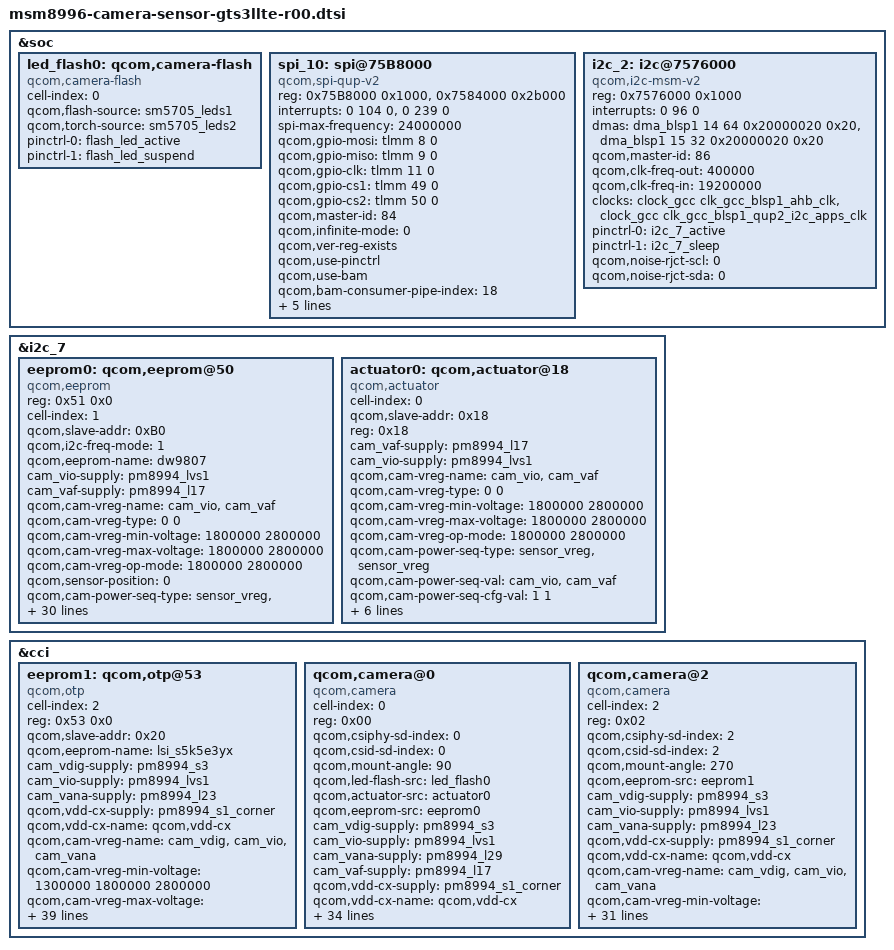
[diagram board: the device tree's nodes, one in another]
/*
 * Copyright (c) 2015 The Linux Foundation. All rights reserved.
 *
 * This program is free software; you can redistribute it and/or modify
 * it under the terms of the GNU General Public License version 2 and
 * only version 2 as published by the Free Software Foundation.
 *
 * This program is distributed in the hope that it will be useful,
 * but WITHOUT ANY WARRANTY; without even the implied warranty of
 * MERCHANTABILITY or FITNESS FOR A PARTICULAR PURPOSE.  See the
 * GNU General Public License for more details.
 */

&soc {
	led_flash0: qcom,camera-flash {
		cell-index = <0>;
		compatible = "qcom,camera-flash";
		qcom,flash-source = <&sm5705_leds1>;
		qcom,torch-source = <&sm5705_leds2>;
		pinctrl-names = "flash_default", "flash_suspend";
		pinctrl-0 = <&flash_led_active>;
		pinctrl-1 = <&flash_led_suspend>;
	};
};

&soc {
	spi_10: spi@75B8000 { /* BLSP2 QUP4 */
		compatible = "qcom,spi-qup-v2";

		reg-names = "spi_physical", "spi_bam_physical";
		reg = <0x75B8000 0x1000>, <0x7584000 0x2b000>;
		interrupt-names = "spi_irq", "spi_bam_irq";
		interrupts = <0 104 0>, <0 239 0>;

		spi-max-frequency = <24000000>;
		#address-cells = <1>;
		#size-cells = <0>;

		qcom,gpio-mosi = <&tlmm 8 0>;
		qcom,gpio-miso = <&tlmm 9 0>;
		qcom,gpio-clk  = <&tlmm 11 0>;
		qcom,gpio-cs1  = <&tlmm 49 0>;
		qcom,gpio-cs2  = <&tlmm 50 0>;

		qcom,master-id = <84>;
		qcom,infinite-mode = <0>;
		qcom,ver-reg-exists;
		qcom,use-pinctrl;
		qcom,use-bam;
		qcom,bam-consumer-pipe-index = <18>;
		qcom,bam-producer-pipe-index = <19>;
		pinctrl-names = "spi_default", "spi_sleep";
		pinctrl-0 = <&spi_10_active &spi_10_cs1_active>;
		pinctrl-1 = <&spi_10_sleep &spi_10_cs1_sleep>;

		clock-names = "iface_clk", "core_clk";

		clocks = <&clock_gcc clk_gcc_blsp2_ahb_clk>,
			 <&clock_gcc clk_gcc_blsp2_qup4_spi_apps_clk>;
	};

	i2c_2: i2c@7576000 { /* BLSP1 QUP2 */
		compatible = "qcom,i2c-msm-v2";
		#address-cells = <1>;
		#size-cells = <0>;
		reg-names = "qup_phys_addr";
		reg = <0x7576000 0x1000>;
		interrupt-names = "qup_irq";
		interrupts = <0 96 0>;
		dmas = <&dma_blsp1 14 64 0x20000020 0x20>,
			<&dma_blsp1 15 32 0x20000020 0x20>;
		dma-names = "tx", "rx";
		qcom,master-id = <86>;
		qcom,clk-freq-out = <400000>;
		qcom,clk-freq-in  = <19200000>;
		clock-names = "iface_clk", "core_clk";
		clocks = <&clock_gcc clk_gcc_blsp1_ahb_clk>,
			<&clock_gcc clk_gcc_blsp1_qup2_i2c_apps_clk>;
		pinctrl-names = "i2c_active", "i2c_sleep";
		pinctrl-0 = <&i2c_7_active>;
		pinctrl-1 = <&i2c_7_sleep>;
		qcom,noise-rjct-scl = <0>;
		qcom,noise-rjct-sda = <0>;
	};
};

&i2c_7 {
	eeprom0: qcom,eeprom@50 {
		compatible = "qcom,eeprom";
		reg = <0x51 0x0>;
		cell-index = <1>;
		qcom,slave-addr = <0xB0>;
		qcom,i2c-freq-mode = <1>;
		qcom,eeprom-name = "dw9807";
		cam_vio-supply = <&pm8994_lvs1>;
		cam_vaf-supply = <&pm8994_l17>;
		qcom,cam-vreg-name = "cam_vio", "cam_vaf";
		qcom,cam-vreg-type = <0 0>;
		qcom,cam-vreg-min-voltage = <1800000 2800000>;
		qcom,cam-vreg-max-voltage = <1800000 2800000>;
		qcom,cam-vreg-op-mode = <1800000 2800000>;

		qcom,sensor-position = <0>;
		qcom,cam-power-seq-type = "sensor_vreg", "sensor_vreg";
		qcom,cam-power-seq-val = "cam_vio", "cam_vaf";
		qcom,cam-power-seq-cfg-val = <1 1>;
		qcom,cam-power-seq-delay = <2 20>;

		qcom,num-blocks = <8>;
		qcom,page0 = <0 0x0 0 0x0 0 0>;
		qcom,poll0 = <0 0x0 0 0x0 0 0>;
		qcom,mem0 = <0xFC 0x0 2 0 1 0>;

		qcom,page1 = <0 0x0 0 0x0 0 0>;
		qcom,poll1 = <0 0x0 0 0x0 0 0>;
		qcom,mem1 = <0x4 0xFC 2 0 1 0>;

		qcom,page2 = <0 0x0 0 0x0 0 0>;
		qcom,poll2 = <0 0x0 0 0x0 0 0>;
		qcom,mem2 = <0x7B0 0x100 2 0 1 0>;

		qcom,page3 = <0 0x0 0 0x0 0 0>;
		qcom,poll3 = <0 0x0 0 0x0 0 0>;
		qcom,mem3 = <0x4 0x8FC 2 0 1 0>;

		qcom,page4 = <0 0x0 0 0x0 0 0>;
		qcom,poll4 = <0 0x0 0 0x0 0 0>;
		qcom,mem4 = <0x20 0x900 2 0 1 0>;

		qcom,page5 = <0 0x0 0 0x0 0 0>;
		qcom,poll5 = <0 0x0 0 0x0 0 0>;
		qcom,mem5 = <0x4 0x9FC 2 0 1 0>;

		qcom,page6 = <0 0x0 0 0x0 0 0>;
		qcom,poll6 = <0 0x0 0 0x0 0 0>;
		qcom,mem6 = <0x700 0xA00 2 0 1 0>;

		qcom,page7 = <0 0x0 0 0x0 0 0>;
		qcom,poll7 = <0 0x0 0 0x0 0 0>;
		qcom,mem7 = <0x4 0x11FC 2 0 1 0>;

		qcom,total-size = <0x1200>;
	};

	actuator0: qcom,actuator@18 {
		compatible = "qcom,actuator";
		cell-index = <0>;
		qcom,slave-addr = <0x18>;
		reg = <0x18>;
		cam_vaf-supply = <&pm8994_l17>;
		cam_vio-supply = <&pm8994_lvs1>;
		qcom,cam-vreg-name = "cam_vio", "cam_vaf";
		qcom,cam-vreg-type = <0 0>;
		qcom,cam-vreg-min-voltage = <1800000 2800000>;
		qcom,cam-vreg-max-voltage = <1800000 2800000>;
		qcom,cam-vreg-op-mode = <1800000 2800000>;

		qcom,cam-power-seq-type = "sensor_vreg", "sensor_vreg";
		qcom,cam-power-seq-val = "cam_vio", "cam_vaf";
		qcom,cam-power-seq-cfg-val = <1 1>;
		qcom,cam-power-seq-delay = <2 1>;

		gpios = <&tlmm 55 0>,
			<&tlmm 56 0>;
		qcom,gpio-req-tbl-num = <0 1>;
		qcom,gpio-req-tbl-flags = <1 1>;
		qcom,gpio-req-tbl-label = "I2C_DATA0",
					  "I2C_CLK0";
		qcom,cci-master = <0>;
	};

};

&spi_10 {

};

&cci {
	eeprom1: qcom,otp@53 {
		cell-index = <2>;
		compatible = "qcom,otp";
		reg = <0x53 0x0>;
		qcom,slave-addr = <0x20>;
		qcom,eeprom-name = "lsi_s5k5e3yx";
		cam_vdig-supply = <&pm8994_s3>;
		cam_vio-supply = <&pm8994_lvs1>;
		cam_vana-supply = <&pm8994_l23>;
		qcom,vdd-cx-supply = <&pm8994_s1_corner>;
		qcom,vdd-cx-name = "qcom,vdd-cx";
		qcom,cam-vreg-name = "cam_vdig", "cam_vio", "cam_vana";
		qcom,cam-vreg-min-voltage = <1300000 1800000 2800000>;
		qcom,cam-vreg-max-voltage = <1300000 1800000 2800000>;
		qcom,cam-vreg-op-mode = <1300000 1800000 2800000>;
		pinctrl-names = "cam_default", "cam_suspend";
		pinctrl-0 = <&cam_sensor_mclk2_active &cam_sensor_front_active>;
		pinctrl-1 = <&cam_sensor_mclk2_suspend &cam_sensor_front_suspend>;
		qcom,gpio-no-mux = <0>;
		gpios = <&tlmm 15 0>,
			<&tlmm 8 0>,
			<&tlmm 40 0>;
		qcom,gpio-vdig = <1>;
		qcom,gpio-reset = <2>;
		qcom,gpio-req-tbl-num = <0 1 2>;
		qcom,gpio-req-tbl-flags = <1 0 0 >;
		qcom,gpio-req-tbl-label = "CAMIF_MCLK",
			"CAM_VDIG",
			"CAM_RESET";
		qcom,sensor-position = <1>;
		qcom,sensor-mode = <0>;
		qcom,cci-master = <1>;
		status = "ok";

		qcom,cam-power-seq-type = "sensor_vreg", "sensor_gpio", "sensor_vreg", "sensor_vreg", "sensor_gpio", "sensor_clk";
		qcom,cam-power-seq-val = "cam_vana", "sensor_gpio_vdig", "cam_vdig", "cam_vio", "sensor_gpio_reset", "sensor_cam_mclk";
		qcom,cam-power-seq-cfg-val = <1 1 1 1 1 24000000>;
		qcom,cam-power-seq-delay = <1 1 1 1 2 5>;

		clocks = <&clock_mmss clk_mclk2_clk_src>,
			<&clock_mmss clk_camss_mclk2_clk>;
		clock-names = "cam_src_clk", "cam_clk";
		qcom,clock-rates = <24000000 0>;

		qcom,num-blocks = <3>;
		qcom,page0 = <0 0 0 0 0 0>;
		qcom,poll0 = <0 0 0 0 0 0>;
		qcom,mem0 = <0x2C 0x10 2 0 0 0>;
		qcom,page1 = <0 0 0 0 0 0>;
		qcom,poll1 = <0 0 0 0 0 0>;
		qcom,mem1 = <0x4 0x3C 2 0 0 0>;
		qcom,page2 = <0 0 0 0 0 0>;
		qcom,poll2 = <0 0 0 0 0 0>;
		qcom,mem2 = <0x40 0x00 2 0 1 0>;
		qcom,total-size = <0x40>;
	};

	qcom,camera@0 {
		cell-index = <0>;
		compatible = "qcom,camera";
		reg = <0x00>;
		qcom,csiphy-sd-index = <0>;
		qcom,csid-sd-index = <0>;
		qcom,mount-angle = <90>;
		qcom,led-flash-src = <&led_flash0>;
		qcom,actuator-src = <&actuator0>;
		qcom,eeprom-src = <&eeprom0>;
		cam_vdig-supply = <&pm8994_s3>;
		cam_vio-supply = <&pm8994_lvs1>;
		cam_vana-supply = <&pm8994_l29>;
		cam_vaf-supply = <&pm8994_l17>;
		qcom,vdd-cx-supply = <&pm8994_s1_corner>;
		qcom,vdd-cx-name = "qcom,vdd-cx";
		qcom,cam-vreg-name = "cam_vana", "cam_vdig", "cam_vaf", "cam_vio";
		qcom,cam-vreg-min-voltage = <2800000 1300000 2800000 1800000>;
		qcom,cam-vreg-max-voltage = <2800000 1300000 2800000 1800000>;
		qcom,cam-vreg-op-mode = <5000 5000 50000 5000>;
		qcom,gpio-no-mux = <0>;
		pinctrl-names = "cam_default", "cam_suspend";
		pinctrl-0 = <&cam_sensor_mclk0_active &cam_sensor_rear_active>;
		pinctrl-1 = <&cam_sensor_mclk0_suspend &cam_sensor_rear_suspend>;
		gpios = <&tlmm 13 0>,
			<&tlmm 30 0>,
			<&tlmm 9 0>;
		qcom,gpio-reset = <1>;
		qcom,gpio-core-en = <2>;
		qcom,gpio-req-tbl-num = <0 1 2>;
		qcom,gpio-req-tbl-flags = <1 0 0>;
		qcom,gpio-req-tbl-label = "CAMIF_MCLK0",
					  "CAM_RESET0" , "CAM_CORE_EN";
		qcom,sensor-position = <0>;
		qcom,sensor-mode = <0>;
		qcom,cci-master = <0>;
		status = "ok";
		clocks = <&clock_mmss clk_mclk0_clk_src>,
				<&clock_mmss clk_camss_mclk0_clk>;
		clock-names = "cam_src_clk", "cam_clk";
		qcom,clock-rates = <24000000 0>;
		cam,isp = <0>;                  // 0 : INT , 1 : EXT , 2 : SOC
		cam,cal_memory = <2>;           // 0 : N , 1 : FROM , 2 : EEPROM , 3 : OTP
		cam,read_version = <0>;         // 0 : SYSFS , 1 : CAMON
		cam,core_voltage = <0>;         // 0 : N , 1 : Y
		cam,upgrade = <0>;              // 0 : N , 1 : SYSFS , 2 : CAMON
		cam,fw_write = <0>;             // 0 : N , 1 : OS , 2 : SD , 3 : ALL
		cam,fw_dump = <0>;              // 0 : N , 1 : Y
		cam,companion_chip = <0>;       // 0 : N , 1 : Y
		cam,ois = <0>;                  // 0 : N , 1 : Y
	};

	qcom,camera@2 {
		cell-index = <2>;
		compatible = "qcom,camera";
		reg = <0x02>;
		qcom,csiphy-sd-index = <2>;
		qcom,csid-sd-index = <2>;
		qcom,mount-angle = <270>;
		qcom,eeprom-src = <&eeprom1>;
		cam_vdig-supply = <&pm8994_s3>;
		cam_vio-supply = <&pm8994_lvs1>;
		cam_vana-supply = <&pm8994_l23>;
		qcom,vdd-cx-supply = <&pm8994_s1_corner>;
		qcom,vdd-cx-name = "qcom,vdd-cx";
		qcom,cam-vreg-name = "cam_vdig", "cam_vio", "cam_vana";
		qcom,cam-vreg-min-voltage = <1300000 1800000 2800000>;
		qcom,cam-vreg-max-voltage = <1300000 1800000 2800000>;
		qcom,cam-vreg-op-mode = <200000 200000 100000>;
		qcom,gpio-no-mux = <0>;
		pinctrl-names = "cam_default", "cam_suspend";
		pinctrl-0 = <&cam_sensor_mclk2_active &cam_sensor_front_active>;
		pinctrl-1 = <&cam_sensor_mclk2_suspend &cam_sensor_front_suspend>;
		gpios = <&tlmm 15 0>,
			<&tlmm 40 0>,
			<&tlmm 8 0>;
		qcom,gpio-reset = <1>;
		qcom,gpio-core-en = <2>;
		qcom,gpio-req-tbl-num = <0 1 2>;
		qcom,gpio-req-tbl-flags = <1 0 0>;
		qcom,gpio-req-tbl-label = "CAMIF_MCLK2",
					  "CAM_RESET2" , "CAM_CORE_EN";
		qcom,sensor-position = <1>;
		qcom,sensor-mode = <0>;
		qcom,cci-master = <1>;
		status = "ok";
		clocks = <&clock_mmss clk_mclk2_clk_src>,
			<&clock_mmss clk_camss_mclk2_clk>;
		clock-names = "cam_src_clk", "cam_clk";
		qcom,clock-rates = <24000000 0>;
		cam,isp = <0>;					// 0 : INT , 1 : EXT , 2 : SOC
		cam,cal_memory = <3>;			// 0 : N , 1 : FROM , 2 : EEPROM , 3 : OTP
		cam,read_version = <0>; 		// 0 : SYSFS , 1 : CAMON
		cam,core_voltage = <0>; 		// 0 : N , 1 : Y
		cam,upgrade = <0>;				// 0 : N , 1 : SYSFS , 2 : CAMON
		cam,fw_write = <0>; 			// 0 : N , 1 : OS , 2 : SD , 3 : ALL
		cam,fw_dump = <0>;				// 0 : N , 1 : Y
		cam,companion_chip = <0>;		// 0 : N , 1 : Y
		cam,ois = <0>;					// 0 : N , 1 : Y
	};
};
